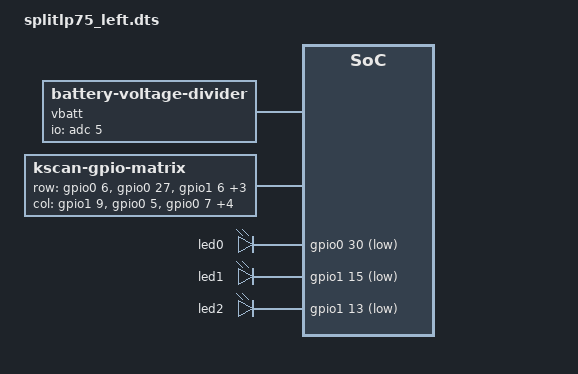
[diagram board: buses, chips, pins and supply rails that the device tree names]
/*
 * Copyright (c) 2024 Andrew Kannan
 *
 * SPDX-License-Identifier: MIT
 */

/dts-v1/;
#include "splitlp75.dtsi"

/ {

    chosen {
        zmk,battery = &vbatt;
    };

    vbatt: vbatt {
        // Left side uses an external DCDC with a voltage divider
        compatible = "zmk,battery-voltage-divider";
        io-channels = <&adc 5>; // Pin AIN5 (P0.29)
        output-ohms = <6800000>; // Lower R = 6.8M
        full-ohms = <(5100000 + 6800000)>; // Ladder = 5.1M + 6.8M
    };

    kscan0: kscan {
        compatible = "zmk,kscan-gpio-matrix";
        wakeup-source;
        label = "KSCAN";

        diode-direction = "col2row";
        row-gpios
            = <&gpio0 6  (GPIO_ACTIVE_HIGH | GPIO_PULL_DOWN)>
            , <&gpio0 27 (GPIO_ACTIVE_HIGH | GPIO_PULL_DOWN)>
            , <&gpio1 6  (GPIO_ACTIVE_HIGH | GPIO_PULL_DOWN)>
            , <&gpio1 7  (GPIO_ACTIVE_HIGH | GPIO_PULL_DOWN)>
            , <&gpio0 26 (GPIO_ACTIVE_HIGH | GPIO_PULL_DOWN)>
            , <&gpio0 4  (GPIO_ACTIVE_HIGH | GPIO_PULL_DOWN)>
            ;
        col-gpios
            = <&gpio1 9  GPIO_ACTIVE_HIGH>
            , <&gpio0 5  GPIO_ACTIVE_HIGH>
            , <&gpio0 7  GPIO_ACTIVE_HIGH>
            , <&gpio1 8  GPIO_ACTIVE_HIGH>
            , <&gpio0 11 GPIO_ACTIVE_HIGH>
            , <&gpio0 12 GPIO_ACTIVE_HIGH>
            , <&gpio1 11 GPIO_ACTIVE_HIGH>
            ;
    };

    leds {
        compatible = "gpio-leds";
        status = "okay";
        led0: led_0 {
            gpios = <&gpio0 30 GPIO_ACTIVE_LOW>;  // Red LED
        };
        led1: led_1 {
            gpios = <&gpio1 15 GPIO_ACTIVE_LOW>;  // Green LED
        };
        led2: led_2 {
            gpios = <&gpio1 13 GPIO_ACTIVE_LOW>;  // Blue LED
        };
    };
};
